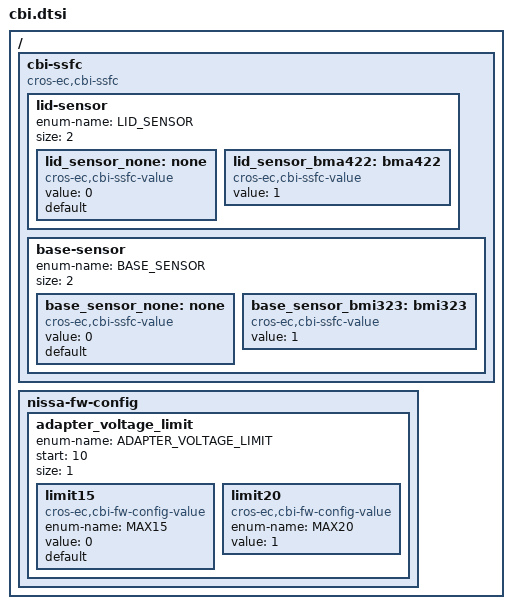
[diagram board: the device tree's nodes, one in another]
/* Copyright 2023 The ChromiumOS Authors
 * Use of this source code is governed by a BSD-style license that can be
 * found in the LICENSE file.
 */

/ {
	/* gothrax-specific ssfc fields. */
	cbi-ssfc {
		compatible = "cros-ec,cbi-ssfc";
		/*
		 * SSFC field to identify LID motion sensor.
		 */
		lid-sensor {
			enum-name = "LID_SENSOR";
			size = <2>;

			lid_sensor_none: none {
				compatible = "cros-ec,cbi-ssfc-value";
				status = "okay";
				value = <0>;
				default;
			};
			lid_sensor_bma422: bma422 {
				compatible = "cros-ec,cbi-ssfc-value";
				status = "okay";
				value = <1>;
			};
		};
		/*
		 * SSFC field to identify BASE motion sensor.
		 */
		base-sensor {
			enum-name = "BASE_SENSOR";
			size = <2>;

			base_sensor_none: none {
				compatible = "cros-ec,cbi-ssfc-value";
				status = "okay";
				value = <0>;
				default;
			};
			base_sensor_bmi323: bmi323 {
				compatible = "cros-ec,cbi-ssfc-value";
				status = "okay";
				value = <1>;
			};
		};
	};
	/* gothrax-specific fw_config fields. */
	nissa-fw-config {
		/*
		 * FW_CONFIG field to extern charger max voltage select 15v/20v
		 */
		adapter_voltage_limit {
			enum-name = "ADAPTER_VOLTAGE_LIMIT";
			start = <10>;
			size = <1>;
			limit15  {
				compatible = "cros-ec,cbi-fw-config-value";
				enum-name = "MAX15";
				value = <0>;
				default;
			};
			limit20 {
				compatible = "cros-ec,cbi-fw-config-value";
				enum-name = "MAX20";
				value = <1>;
			};
		};
	};
};
